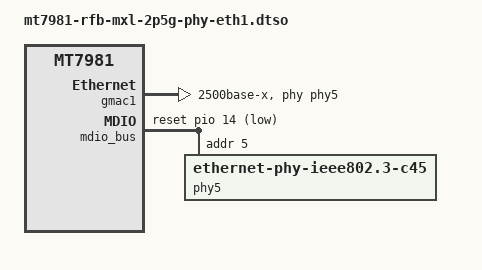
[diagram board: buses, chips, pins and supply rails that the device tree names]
/* SPDX-License-Identifier: (GPL-2.0-only OR MIT) */
/dts-v1/;
/plugin/;

#include <dt-bindings/gpio/gpio.h>

/ {
	compatible = "mediatek,mt7981-rfb", "mediatek,mt7981";

	fragment@0 {
		target = <&gmac1>;
		__overlay__ {
			phy-mode = "2500base-x";
			phy-handle = <&phy5>;
		};
	};

	fragment@1 {
		target = <&mdio_bus>;
		__overlay__ {
			reset-gpios = <&pio 14 GPIO_ACTIVE_LOW>;
			reset-delay-us = <600>;
			reset-post-delay-us = <20000>;

			phy5: ethernet-phy@5 {
				reg = <5>;
				compatible = "ethernet-phy-ieee802.3-c45";
				phy-mode = "2500base-x";
			};
		};
	};
};
